# HWSEQ_L3Interconnect register map
Vendor: Texas Instruments
Peripheral module from a debugger description file (folder omap4430).
Registers are 32-bit, access per field, reset 0x0 unless marked. A register's access mark holds for its fields unless they carry their own. Offsets are as the file gives them; lines under a group give offsets from that group; [hi:lo] are bit positions; {n}, {i} and the like mark numbered series; 'fields as' and 'values as' point back to an identical list; <NAME> marks a mode.

## HWSEQ_L3Interconnect
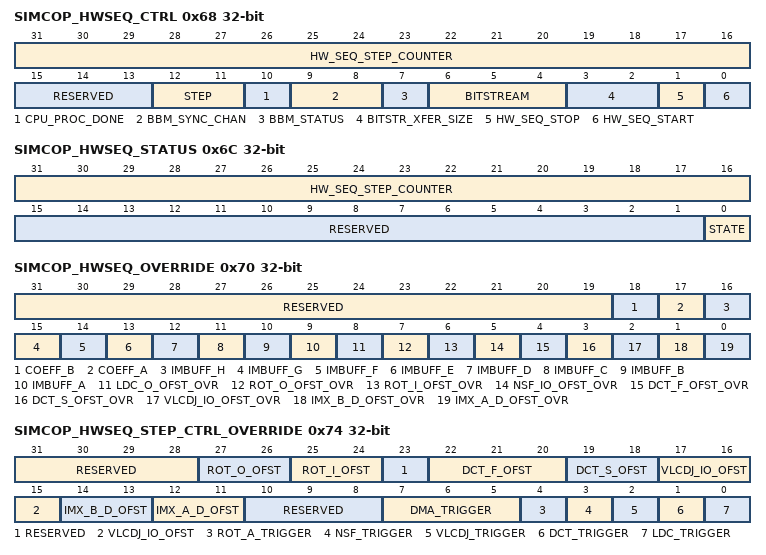
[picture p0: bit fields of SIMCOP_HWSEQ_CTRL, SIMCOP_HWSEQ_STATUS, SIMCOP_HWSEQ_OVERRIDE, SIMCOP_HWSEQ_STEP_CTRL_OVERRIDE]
0x68 SIMCOP_HWSEQ_CTRL — SIMCOP hardware sequencer control register
  [31:16] HW_SEQ_STEP_COUNTER rw — Number of steps executed by the hardware sequencer. HW_SEQ_STEP_COUNTER=0 corresponds to manual sequencing.
  [15:13] RESERVED ro — Read returns 0.
  [12:11] STEP rw — This register is automatically updated by the hardware sequencer when it is active. Otherwise, software can use it to activate the content of a given set of step registers (SIMCOP_HWSEQ_STEP_i) or to choose the first step number of a sequence.
  [10] CPU_PROC_DONE wo — Used by the CPU to tell that it has completed data processing. This feature should be used together with the CPU_PROC_START_IRQ event Read's always return 0.
    0=CPU_PROC_DONE_0_w (No effect.); 1=CPU_PROC_DONE_1_w (CPU processing completed.)
  [9:8] BBM_SYNC_CHAN rw — Defines the SIMCOP DMA hardware synchronization channel to be used for BBM. This register is only used when BITSTREAM=ENCODE or DECODE. Software must ensure that the same DMA hardware synchronization channel is not used by the hardware sequencer.
  [7] BBM_STATUS ro — Status of the Bitstream buffer management hardware.Used only during automatic mode [BITSTREAM=5 or 6]. Equals 0 (IDLE) in manual mode [BITSTREAM=0..4].Set when automatic mode is entered. Automatic encode mode: used to detect when all banks have been flushed after the processing has completed (i.e. but request bank signals have been de-asserted by BBM). Automatic decode mode (BITSTREAM=DECODE): returns to 0 (IDLE) when automatic mode is left (BITSTREAM=COPR).Read 0x1: BBM is busy.Read 0x0: BBM is idle
  [6:4] BITSTREAM rw — Bitstream buffer access control
    0=Bank 0: coprocessor bus (0x1000-0x17FF) Bank 1: coprocessor bus (0x1800-0x1FFF); 1=Bank 0: DMA (0x1000-0x17FF) Bank 1: DMA (0x1800-0x1FFF); 2=Bank 0: VLCDJ.B (0x000-0x7FF) Bank 1: VLCDJ.B (0x800-0xFFF); 3=Bank 0: DMA (0x1000-0x17FF) Bank 1: VLCDJ.B (0x800-0xFFF); 4=Bank 0: VLCDJ.B (0x000-0x7FF) Bank 1: DMA (0x1800-0x1FFF); 5=The bitstream buffer is managed by hardware as a PING/PONG buffer to support JPEG encode use case. It can be accessed by the SIMCOP DMA or the VLCDJ module. The BITSTREAM hardware sequence is reset when the mode is changed to COPR, VLCDJ or DMA.; 6=The bitstream buffer is managed by hardware as a PING/PONG buffer to support JPEG decode use case. It can be accessed by the SIMCOP DMA or the VLCDJ module. The BITSTREAM hardware sequence is reset when the mode is changed to COPR, VLCDJ or DMA.
  [3:2] BITSTR_XFER_SIZE rw — Defines the amount of data to be transferred per hardware request to the SIMCOP DMA. Bigger sizes lead to better SDRAM efficiency but prevents fine grained DMA transfer arbitration. This register is only used by hardware when BITSTREAM=ENCODE or BITSTREAM=DECODE.
    0=2048 bytes; 1=1024 bytes; 2=512 bytes; 3=256 bytes
  [1] HW_SEQ_STOP wo — Stop the hardware sequencer. This feature is typically used to recover from an error condition. Read's always return 0.
    0=HW_SEQ_STOP_0_w (No effect.); 1=HW_SEQ_STOP_1_w (Stop the hardware sequence immediately (don't wait for expected DONE events). Setting this bit while the sequencer is idle has no effect.)
  [0] HW_SEQ_START wo — Start the hardware sequencer. Read's always return 0.
    0=HW_SEQ_START_0_w (No effect.); 1=HW_SEQ_START_1_w (Starts step number[12:11] STEP of the hardware sequence. Setting this bit while the sequencer is running has no effect.)
0x6C SIMCOP_HWSEQ_STATUS ro — Hardware sequencer status register
  [31:16] HW_SEQ_STEP_COUNTER — Current step number
  [15:1] RESERVED — Read returns 0.
  [0] STATE — Current state
    0=STATE_0_r (Idle); 1=STATE_1_r (Running)
0x70 SIMCOP_HWSEQ_OVERRIDE — Hardware sequencer override control register. Bits in this register select what configuration register control a resource. 0: Resource controlled by hardware sequencer. Hardware uses the value from SIMCOP_HWSEQ_STEP_xx registers for the chosen resource 1: Resource controlled by software. Hardware uses the value from SIMCOP_HWSEQ_STEP_x_OVERRIDE registers for the chosen resource The bit field name matches the one of the resource.For example, IMX_A_D_OFST_OVR selects if
  [31:19] RESERVED ro — Read returns 0.
  [18] COEFF_B rw — See register description
  [17] COEFF_A rw — See register description
  [16] IMBUFF_H rw — See register description
  [15] IMBUFF_G rw — See register description
  [14] IMBUFF_F rw — See register description
  [13] IMBUFF_E rw — See register description
  [12] IMBUFF_D rw — See register description
  [11] IMBUFF_C rw — See register description
  [10] IMBUFF_B rw — See register description
  [9] IMBUFF_A rw — See register description
  [8] LDC_O_OFST_OVR rw — See register description
  [7] ROT_O_OFST_OVR rw — See register description
  [6] ROT_I_OFST_OVR rw — See register description
  [5] NSF_IO_OFST_OVR rw — See register description
  [4] DCT_F_OFST_OVR rw — See register description
  [3] DCT_S_OFST_OVR rw — See register description
  [2] VLCDJ_IO_OFST_OVR rw — See register description
  [1] IMX_B_D_OFST_OVR rw — See register description
  [0] IMX_A_D_OFST_OVR rw — See register description
0x74 SIMCOP_HWSEQ_STEP_CTRL_OVERRIDE — Hardware sequencer override register. Used to execute software sequences in parallel to hardware sequencing steps
  [31:28] RESERVED ro — Read returns 0.
  [27:26] ROT_O_OFST rw — Controls ROT.O bus mapping to image buffers: 0x0000 0x1000 0x2000 0x3000
    0=EFGH; 1=FGHE; 2=GHEF; 3=HEFG
  [25:24] ROT_I_OFST rw — Controls ROT_I bus mapping to image buffers: 0x0000 0x1000 0x2000 0x3000
    0=ABCD; 1=BCDA; 2=CDAB; 3=DABC
  [23] RESERVED ro — Read returns 0.
  [22:20] DCT_F_OFST rw — Controls DCT.F bus mapping to image buffers: 0x0000 0x1000 0x2000 0x3000
    0=ABCD; 1=BCDG; 2=CDGH; 3=DGHA; 4=GHAB; 5=HABC
  [19:18] DCT_S_OFST rw — Controls DCT.S bus mapping to image buffers: 0x0000 0x1000
    0=EF; 1=FG; 2=GH; 3=HE
  [17:15] VLCDJ_IO_OFST rw — Controls VLCDJ IO data bus mapping to image buffers: 0x0000 0x1000 0x2000 0x3000
    0=ABCD; 1=BCDG; 2=CDGH; 3=DGHA; 4=GHAB; 5=HABC
  [14:13] IMX_B_D_OFST rw — Controls iMX B data bus mapping to image buffers: 0x0000 0x1000 0x2000 0x3000
    0=ABCD; 1=CDEF; 2=EFGH; 3=GHAB
  [12:11] IMX_A_D_OFST rw — Controls iMX A data bus mapping to image buffers: 0x0000 0x1000 0x2000 0x3000
    0=ABCD; 1=CDEF; 2=EFGH; 3=GHAB
  [10:8] RESERVED ro — Read returns 0.
  [7:5] DMA_TRIGGER rw — Software controlled START/DONE synchronization
    0=DMA_TRIGGER_0_w (No effect); 0=DMA_TRIGGER_0_r (No done pulse have been received since last non zero write into the DMA_TRIGGER register); 1=DMA_TRIGGER_1_r (DONE pulses for channel 0 and 1 have been received); 1=DMA_TRIGGER_1_w (Trigger channel 0 and 1. Clears all memorized done pulses for DMA.); 2=DMA_TRIGGER_2_w (Trigger channel 0, 1, 2. Clears all memorized done pulses for DMA.); 2=DMA_TRIGGER_2_r (DONE pulses for channel 0, 1 and 2 have been received); 3=DMA_TRIGGER_3_r (DONE pulses for channel 0, 1, 2 and 3 have been received.); 3=DMA_TRIGGER_3_w (Trigger channel 0, 1, 2 and 3. Clears all memorized done pulses for DMA.); {v}=DMA_TRIGGER_{v}_r (DONE pulse for channel {v-4} has been received) (v=4..7); {v}=DMA_TRIGGER_{v}_w (Trigger channel {v-4}. Clears all memorized done pulses for DMA.) (v=4..7)
  [4] ROT_A_TRIGGER rw — Software controlled START/DONE synchronization
    0=ROT_A_TRIGGER_0_w (No Effect); 0=ROT_A_TRIGGER_0_r (No DONE pulse received since the last START pulse has been sent); 1=ROT_A_TRIGGER_1_r (DONE pulse received); 1=ROT_A_TRIGGER_1_w (Send a start pulse and clears the memorized done pulse)
  [3] NSF_TRIGGER rw — Software controlled START/DONE synchronization
    0=NSF_TRIGGER_0_w (No Effect); 0=NSF_TRIGGER_0_r (No DONE pulse received since the last START pulse has been sent); 1=NSF_TRIGGER_1_r (DONE pulse received); 1=NSF_TRIGGER_1_w (Send a start pulse and clears the memorized done pulse)
  [2] VLCDJ_TRIGGER rw — Software controlled START/DONE synchronization
    0=VLCDJ_TRIGGER_0_w (No Effect); 0=VLCDJ_TRIGGER_0_r (No DONE pulse received since the last START pulse has been sent); 1=VLCDJ_TRIGGER_1_r (DONE pulse received); 1=VLCDJ_TRIGGER_1_w (Send a start pulse and clears the memorized done pulse)
  [1] DCT_TRIGGER rw — Software controlled START/DONE synchronization
    0=DCT_TRIGGER_0_w (No Effect); 0=DCT_TRIGGER_0_r (No DONE pulse received since the last START pulse has been sent); 1=DCT_TRIGGER_1_r (DONE pulse received); 1=DCT_TRIGGER_1_w (Send a start pulse and clears the memorized done pulse)
  [0] LDC_TRIGGER rw — Software controlled START/DONE synchronization
    0=LDC_TRIGGER_0_w (No Effect); 0=LDC_TRIGGER_0_r (No DONE pulse received since the last START pulse has been sent); 1=LDC_TRIGGER_1_r (DONE pulse received); 1=LDC_TRIGGER_1_w (Send a start pulse and clears the memorized done pulse)
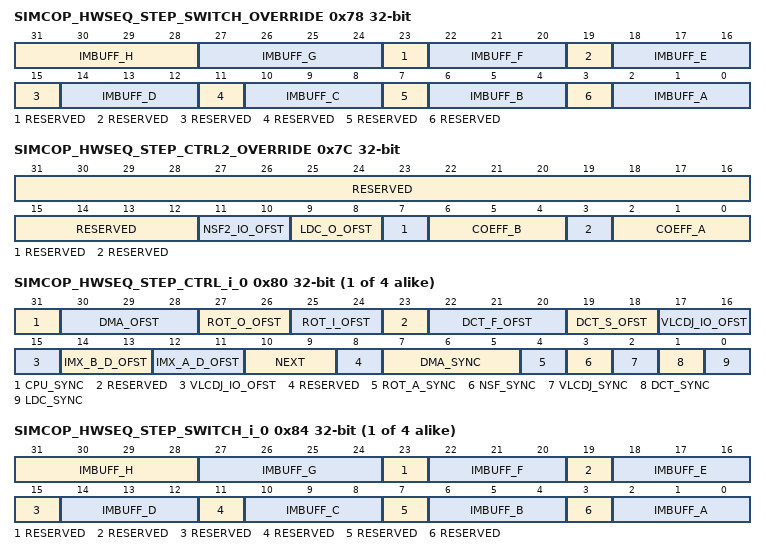
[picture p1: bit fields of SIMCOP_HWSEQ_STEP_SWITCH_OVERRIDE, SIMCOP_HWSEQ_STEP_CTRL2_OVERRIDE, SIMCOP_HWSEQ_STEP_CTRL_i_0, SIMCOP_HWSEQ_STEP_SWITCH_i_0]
0x78 SIMCOP_HWSEQ_STEP_SWITCH_OVERRIDE — Hardware sequencer override register. Used to execute software sequences in parallel to hardware sequencing steps
  [31:28] IMBUFF_H rw — Switch for image buffer h
    0=Coprocessor bus; 1=SIMCOP DMA; 2=iMX A; 3=iMX B; 4=VLCDJ_IO; 5=DCT_S; 6=DCT_F; 7=ROT_A_O; 8=NSF_IO; 9=LDC_O
  [27:24] IMBUFF_G rw — Switch for image buffer g
    values as IMBUFF_H
  [23] RESERVED ro — Read returns 0.
  [22:20] IMBUFF_F rw — Switch for image buffer f
    0=Coprocessor bus; 1=SIMCOP DMA; 2=iMX A; 3=iMX B; 4=DCT_S; 5=NSF_IO; 6=LDC_O; 7=ROT_A_O
  [19] RESERVED ro — Read returns 0.
  [18:16] IMBUFF_E rw — Switch for image buffer e
    values as IMBUFF_F
  [15] RESERVED ro — Read returns 0.
  [14:12] IMBUFF_D rw — Switch for image buffer d
    0=Coprocessor bus; 1=SIMCOP DMA; 2=iMX A; 3=iMX B; 4=VLCDJ_IO; 5=DCT_F; 6=ROT_A_I
  [11] RESERVED ro — Read returns 0.
  [10:8] IMBUFF_C rw — Switch for image buffer c.
    values as IMBUFF_D
  [7] RESERVED ro — Read returns 0.
  [6:4] IMBUFF_B rw — Switch for image buffer b.
    0=Coprocessor bus; 1=SIMCOP DMA; 2=iMX A IMBUFF; 3=iMX B IMBUFF; 4=VLCDJ_IO; 5=DCT_F; 6=ROT_A_I
  [3] RESERVED ro — Read returns 0.
  [2:0] IMBUFF_A rw — Switch for image buffer a
    values as IMBUFF_B
0x7C SIMCOP_HWSEQ_STEP_CTRL2_OVERRIDE — Hardware sequencer override register. Used to execute software sequences in parallel to hardware sequencing steps
  [31:12] RESERVED ro — Read returns 0.
  [11:10] NSF2_IO_OFST rw — Controls NSF_IO bus mapping to image buffers: 0x0000 0x1000
    0=EF; 1=FG; 2=GH; 3=HE
  [9:8] LDC_O_OFST rw — Controls LDC.O bus mapping to image buffers: 0x0000 0x1000 0x2000 0x3000
    0=EFGH; 1=FGHE; 2=GHEF; 3=HEFG
  [7] RESERVED ro — Read returns 0.
  [6:4] COEFF_B rw — Coefficient buffer b switch
    0=Coprocessor bus; 1=SIMCOP DMA; 2=iMX A; 3=iMX B; 4=VLCDJ_IO; 5=DCT_F; 6=ROT A O
  [3] RESERVED ro — Read returns 0.
  [2:0] COEFF_A rw — Coefficient buffer a switch
    0=Coprocessor bus; 1=SIMCOP DMA; 2=iMX A; 3=iMX B; 4=VLCDJ_IO; 5=DCT_F; 6=ROT A I
{0x80+0x10*i} SIMCOP_HWSEQ_STEP_CTRL_i_{i} (i=0..3) — Hardware sequencer step control register
  [31] CPU_SYNC rw — Enable hardware synchronization with the CPU so that it can be used for some processing on in the macroblock pipeline.
    0=Disabled; 1=Enabled
  [30:28] DMA_OFST rw — Controls DMA bus mapping to image buffers: 0x0000 0x1000 0x2000 0x3000 0x4000 0x5000 0x6000 0x7000
    0=ABCDEFGH; 1=BCDEFGHA; 2=CDEFGHAB; 3=DEFGHABC; 4=EFGHABCD; 5=FGHABCDE; 6=GHABCDEF; 7=HABCDEFG
  [27:26] ROT_O_OFST rw — Controls ROT.O bus mapping to image buffers: 0x0000 0x1000 0x2000 0x3000
    0=EFGH; 1=FGHE; 2=GHEF; 3=HEFG
  [25:24] ROT_I_OFST rw — Controls ROT_I bus mapping to image buffers: 0x0000 0x1000 0x2000 0x3000
    0=ABCD; 1=BCDA; 2=CDAB; 3=DABC
  [23] RESERVED ro — Read returns 0.
  [22:20] DCT_F_OFST rw — Controls DCT.F bus mapping to image buffers: 0x0000 0x1000 0x2000 0x3000
    0=ABCD; 1=BCDG; 2=CDGH; 3=DGHA; 4=GHAB; 5=HABC
  [19:18] DCT_S_OFST rw — Controls DCT.S bus mapping to image buffers: 0x0000 0x1000
    0=EF; 1=FG; 2=GH; 3=HE
  [17:15] VLCDJ_IO_OFST rw — Controls VLCDJ IO data bus mapping to image buffers: 0x0000 0x1000 0x2000 0x3000
    0=ABCD; 1=BCDG; 2=CDGH; 3=DGHA; 4=GHAB; 5=HABC
  [14:13] IMX_B_D_OFST rw — Controls iMX B data bus mapping to image buffers: 0x0000 0x1000 0x2000 0x3000
    0=ABCD; 1=CDEF; 2=EFGH; 3=GHAB
  [12:11] IMX_A_D_OFST rw — Controls iMX A data bus mapping to image buffers: 0x0000 0x1000 0x2000 0x3000
    0=ABCD; 1=CDEF; 2=EFGH; 3=GHAB
  [10:9] NEXT rw — Next channel in the sync chain
    {v}=Step {v} (v=0..3)
  [8] RESERVED ro — Read returns 0.
  [7:5] DMA_SYNC rw — Enable hardware synchronization with the SIMCOP DMA
    0=Disabled; 1=Channel 0 and 1; 2=Channel 0, 1, 2; 3=Channel 0, 1, 2 and 3; {v}=Channel {v-4} (v=4..7)
  [4] ROT_A_SYNC rw — Enable hardware synchronization with the ROT #a module
    0=Disabled; 1=Enabled
  [3] NSF_SYNC rw — Enable hardware synchronization with the NSF module
    0=Disabled; 1=Enabled
  [2] VLCDJ_SYNC rw — Enable hardware synchronization with the VLCDJ module
    0=Disabled; 1=Enabled
  [1] DCT_SYNC rw — Enable hardware synchronization with the DCT module
    0=Disabled; 1=Enabled
  [0] LDC_SYNC rw — Enable hardware synchronization with the LDC module
    0=Disabled; 1=Enabled
{0x84+0x10*i} SIMCOP_HWSEQ_STEP_SWITCH_i_{i} (i=0..3) — Image buffer switch control. The configuration of step #0 is used when hardware sequencer is idle.
  fields as SIMCOP_HWSEQ_STEP_SWITCH_OVERRIDE
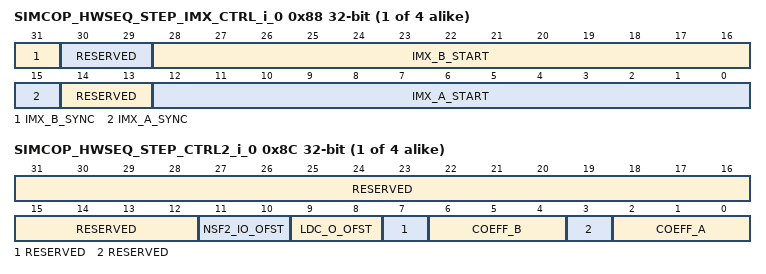
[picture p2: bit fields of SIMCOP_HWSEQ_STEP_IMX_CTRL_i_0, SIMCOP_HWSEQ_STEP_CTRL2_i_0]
{0x88+0x10*i} SIMCOP_HWSEQ_STEP_IMX_CTRL_i_{i} (i=0..3) — Hardware sequencer step control register The configuration of step #0 is used when hardware sequencer is idle.
  [31] IMX_B_SYNC rw — Enable hardware synchronization with the iMX B module
    0=Disabled; 1=Enabled
  [30:29] RESERVED ro — Read returns 0.
  [28:16] IMX_B_START rw — This register is only used whenSIMCOP_HWSEQ_STEP_IMX_CTRL_i[31] IMX_B_SYNC=1. It contains the address, in 16-bit words, of the first instruction iMX will execute when it gets started.
  [15] IMX_A_SYNC rw — Enable hardware synchronization with the iMX A module
    0=Disabled; 1=Enabled
  [14:13] RESERVED ro — Read returns 0.
  [12:0] IMX_A_START rw — This register is only used whenSIMCOP_HWSEQ_STEP_IMX_CTRL_i[15] IMX_A_SYNC=1. It contains the address, in 16-bit words, of the first instruction iMX will execute when it gets started.
{0x8C+0x10*i} SIMCOP_HWSEQ_STEP_CTRL2_i_{i} (i=0..3) — Hardware sequencer step control register
  fields as SIMCOP_HWSEQ_STEP_CTRL2_OVERRIDE
